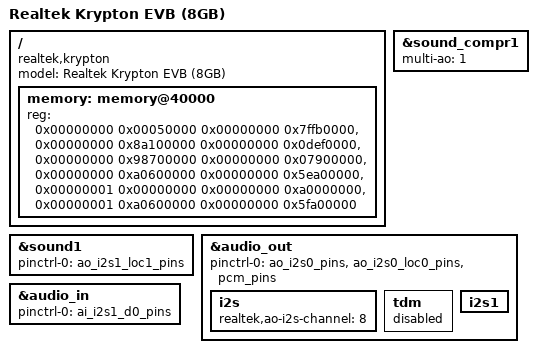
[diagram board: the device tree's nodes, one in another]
// SPDX-License-Identifier: (GPL-2.0-or-later OR BSD-2-Clause)
/*
 * Realtek RTD1861B Krypton EVB
 *
 * Copyright (c) 2024 Realtek Semiconductor Corp.
 */

/dts-v1/;

#include "rtd1861b-krypton.dtsi"

/ {
	compatible = "realtek,krypton", "realtek,rtd1861b";
	model = "Realtek Krypton EVB (8GB)";

	memory: memory@40000 {
		device_type = "memory";
		reg = <0x00000000 0x00050000 0x00000000 0x7ffb0000>,
		      <0x00000000 0x8a100000 0x00000000 0x0def0000>,
		      <0x00000000 0x98700000 0x00000000 0x07900000>,
		      <0x00000000 0xa0600000 0x00000000 0x5ea00000>,
		      <0x00000001 0x00000000 0x00000000 0xa0000000>,
		      <0x00000001 0xa0600000 0x00000000 0x5fa00000>;
	};
};

&sound1 {
	pinctrl-names = "default";
	pinctrl-0 = <&ao_i2s1_loc1_pins>;
	status = "okay";
};

&sound_compr1 {
	multi-ao = <1>;
	status = "okay";
};

&audio_out {
	pinctrl-names = "default";
	pinctrl-0 = <&ao_i2s0_pins>, <&ao_i2s0_loc0_pins>, <&pcm_pins>;
	status = "okay";
	i2s {
		realtek,ao-i2s-channel = <8>;
		status = "okay";
	};
	tdm {
		status = "disabled";
	};
	i2s1 {
		status = "okay";
	};
};

&audio_in {
	pinctrl-names = "default";
	pinctrl-0 = <&ai_i2s1_d0_pins>;
	status = "okay";
};
